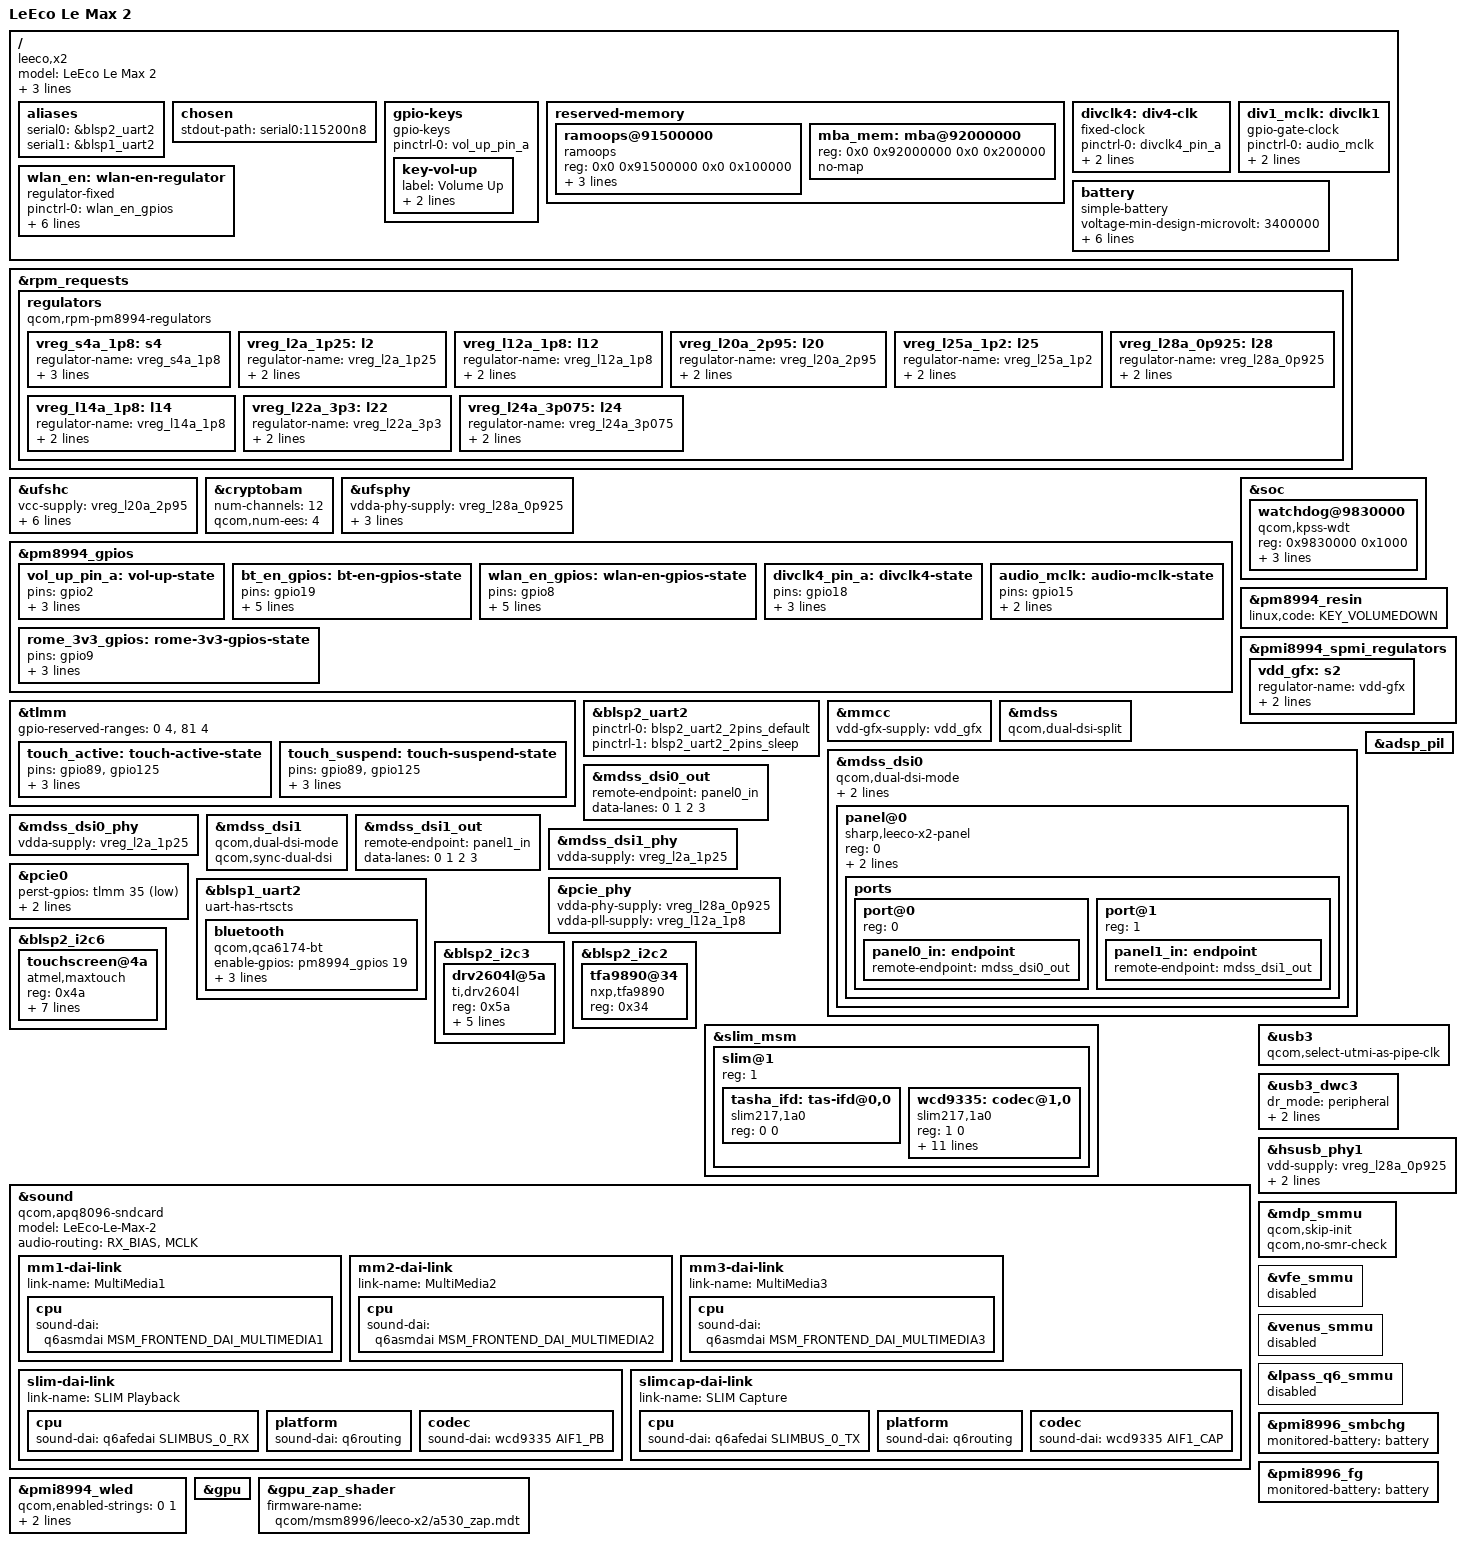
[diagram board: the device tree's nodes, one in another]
// SPDX-License-Identifier: (GPL-2.0+ OR BSD-3-Clause)
/*
 * LeEco Le Max 2 (x2 / LEX820)
 *
 * MSM8996 v3 + PMI8996, 5.7" 1440x2560 dual-DSI panel.
 *
 * Board identification values were read from the live device:
 *   /proc/device-tree/qcom,msm-id    = <0xf6 0x30001>
 *   /proc/device-tree/qcom,board-id  = <0x08 0x2e>
 *   /proc/device-tree/qcom,pmic-id   = <0x20009 0x10013 0x00 0x00>
 *
 * NOTE 1: msm8996-v3.0.dtsi pins qcom,msm-id to <246 0x30000>, but this
 * device reports <246 0x30001>. We therefore include plain msm8996.dtsi
 * (the 3.1 revision) and set the correct msm-id ourselves. This matches
 * what oneplus3 does (it also uses 0x30001 via msm8996.dtsi).
 *
 * NOTE 2: Three DTB variants share board-id 0x2e in the stock boot.img
 * (v3+PMI8996, v3+PMI8994, 8996Pro+PMI8996). The device actually boots the
 * v3+PMI8996 one, which is what we model here.
 */

/dts-v1/;

#include "msm8996.dtsi"
#include "pm8994.dtsi"
#include "pmi8994.dtsi"
#include "pmi8996.dtsi"
#include <dt-bindings/gpio/gpio.h>
#include <dt-bindings/input/input.h>
#include <dt-bindings/input/ti-drv260x.h>
#include <dt-bindings/interrupt-controller/irq.h>
#include <dt-bindings/pinctrl/qcom,pmic-gpio.h>
#include <dt-bindings/sound/qcom,q6afe.h>
#include <dt-bindings/sound/qcom,q6asm.h>
#include <dt-bindings/sound/qcom,wcd9335.h>

/ {
	model = "LeEco Le Max 2";
	compatible = "leeco,x2", "qcom,msm8996";
	chassis-type = "handset";

	qcom,msm-id = <246 0x30001>;
	qcom,board-id = <0x08 0x2e>;

	aliases {
		/* BLSP2 UART2 is the debug console and keeps ttyMSM0. */
		serial0 = &blsp2_uart2;
		/* BLSP1 UART2 is the QCA6174 HCI transport and must not share
		 * line 0 with the console. */
		serial1 = &blsp1_uart2;
	};

	chosen {
		stdout-path = "serial0:115200n8";
	};

	gpio-keys {
		compatible = "gpio-keys";
		pinctrl-names = "default";
		pinctrl-0 = <&vol_up_pin_a>;

		key-vol-up {
			label = "Volume Up";
			linux,code = <KEY_VOLUMEUP>;
			/* vendor mtp-le-common.dtsi:710 - vol_up is pm8994 gpio2 */
			gpios = <&pm8994_gpios 2 GPIO_ACTIVE_LOW>;
		};
	};

	reserved-memory {
		#address-cells = <2>;
		#size-cells = <2>;
		ranges;

		/*
		 * ramoops: MUST live at 0x91500000 - that is where the stock
		 * 3.18 kernel and TWRP look for console-ramoops on this device
		 * (msm8996-le-common.dtsi: ramoops_region@91500000). Anything
		 * written elsewhere is invisible after rebooting back to
		 * Android/TWRP.
		 *
		 * The sub-buffer sizes MUST match the stock 3.18 kernel's
		 * ramoops module params exactly (console_size=0x40000,
		 * record_size=0x10000, pmsg_size=0x20000, ecc=0) and the
		 * kernel's allocation order (dmesg records first, then
		 * console, then pmsg) so that records written by one kernel
		 * are parseable by the other. In particular console-size
		 * 0x60000 made our records unreadable by 3.18.
		 */
		ramoops@91500000 {
			compatible = "ramoops";
			reg = <0x0 0x91500000 0x0 0x100000>;
			console-size = <0x40000>;
			record-size  = <0x10000>;
			pmsg-size    = <0x20000>;
		};

		/* relocated from 0x91500000, which the stock ramoops uses;
		 * same label kept so the mba remoteproc reference resolves */
		/delete-node/ mba@91500000;
		mba_mem: mba@92000000 {
			reg = <0x0 0x92000000 0x0 0x200000>;
			no-map;
		};
	};
};

/*
 * PM8994 RPM regulators.
 *
 * These labels are NOT inherited from pm8994.dtsi - every msm8996 board
 * declares the rails it actually uses under &rpm_requests. We only define
 * the ones referenced below; the voltage values match the oneplus3 and
 * xiaomi-msm8996 boards, which use an identical UFS supply arrangement.
 */
&rpm_requests {
	regulators {
		compatible = "qcom,rpm-pm8994-regulators";

		vreg_s4a_1p8: s4 {
			regulator-name = "vreg_s4a_1p8";
			regulator-min-microvolt = <1800000>;
			regulator-max-microvolt = <1800000>;
			regulator-always-on;
		};

		vreg_l2a_1p25: l2 {
			regulator-name = "vreg_l2a_1p25";
			regulator-min-microvolt = <1250000>;
			regulator-max-microvolt = <1250000>;
		};

		vreg_l12a_1p8: l12 {
			regulator-name = "vreg_l12a_1p8";
			regulator-min-microvolt = <1800000>;
			regulator-max-microvolt = <1800000>;
		};

		vreg_l20a_2p95: l20 {
			regulator-name = "vreg_l20a_2p95";
			regulator-min-microvolt = <2950000>;
			regulator-max-microvolt = <2950000>;
		};

		vreg_l25a_1p2: l25 {
			regulator-name = "vreg_l25a_1p2";
			regulator-min-microvolt = <1200000>;
			regulator-max-microvolt = <1200000>;
		};

		vreg_l28a_0p925: l28 {
			regulator-name = "vreg_l28a_0p925";
			regulator-min-microvolt = <925000>;
			regulator-max-microvolt = <925000>;
		};

		/* rails for peripherals: touch (l14/l22), usb dpdm (l24) */
		vreg_l14a_1p8: l14 {
			regulator-name = "vreg_l14a_1p8";
			regulator-min-microvolt = <1800000>;
			regulator-max-microvolt = <1800000>;
		};

		vreg_l22a_3p3: l22 {
			regulator-name = "vreg_l22a_3p3";
			regulator-min-microvolt = <3300000>;
			regulator-max-microvolt = <3300000>;
		};

		vreg_l24a_3p075: l24 {
			regulator-name = "vreg_l24a_3p075";
			regulator-min-microvolt = <3075000>;
			regulator-max-microvolt = <3075000>;
		};
	};
};

/*
 * UFS: Samsung KLUCG4J1CB-B0B1, 6 LUNs.
 * This is the first thing that must work - without rootfs there is no boot.
 * Supply assignment matches oneplus3 / xiaomi-msm8996, which use the same
 * PM8994 rail layout for UFS.
 */
&ufshc {
	status = "okay";

	vcc-supply = <&vreg_l20a_2p95>;
	vccq-supply = <&vreg_l25a_1p2>;
	vccq2-supply = <&vreg_s4a_1p8>;
	vdd-hba-supply = <&vreg_l25a_1p2>;

	vcc-max-microamp = <600000>;
	vccq-max-microamp = <450000>;
	vccq2-max-microamp = <450000>;
};

/*
 * CE1 BAM. The crypto engine uses pipes 6/7, and the BAM block itself is
 * controlled by the secure firmware, so the Linux side only needs the channel
 * map. msm8937/msm8998 use the same CE BAM topology (12 channels, 4 EEs).
 */
&cryptobam {
	num-channels = <12>;
	qcom,num-ees = <4>;
};

&ufsphy {
	status = "okay";

	vdda-phy-supply = <&vreg_l28a_0p925>;
	vdda-pll-supply = <&vreg_l12a_1p8>;

	vdda-phy-max-microamp = <89700>;
	vdda-pll-max-microamp = <18300>;
};

/* Volume keys live on PMIC GPIOs */
&pm8994_gpios {
	vol_up_pin_a: vol-up-state {
		pins = "gpio2";
		function = PMIC_GPIO_FUNC_NORMAL;
		bias-pull-up;
		input-enable;
	};
};

&tlmm {
	gpio-reserved-ranges = <0 4>, <81 4>;
};

/*
 * APSS hardware watchdog. The vendor 3.18 DTS exposes this at 0x9830000
 * as "qcom,wdt"; mainline has no node, so PSCI reset is the only restart
 * path and a failed PSCI reset leaves the SoC spinning in machine_restart().
 */
&soc {
	watchdog@9830000 {
		compatible = "qcom,kpss-wdt";
		reg = <0x9830000 0x1000>;
		interrupts = <0 28 1>, <0 29 1>;
		clocks = <&sleep_clk>;
		timeout-sec = <30>;
	};
};

/*
 * Debug UART - invaluable when the display does not work yet.
 *
 * The x2 console is BLSP2_UART1 (uart8) on gpio4/5 = mainline blsp2_uart2
 * (serial@75b0000), exactly as the vendor pinctrl uart_console_active and
 * the downstream uart_dm_init(8, BLSP2_UART1_BASE) both show. blsp1_uart2 is the
 * BT/hs-uart on gpio41-44 - enabling it was wrong.
 */
&blsp2_uart2 {
	pinctrl-names = "default", "sleep";
	pinctrl-0 = <&blsp2_uart2_2pins_default>;
	pinctrl-1 = <&blsp2_uart2_2pins_sleep>;
	status = "okay";
};

&pm8994_resin {
	status = "okay";
	linux,code = <KEY_VOLUMEDOWN>;
};

/*
 * GPU supply: PMI8994 S2 is VDD_GFX. The MMCC GPU_GX_GDSC (and therefore
 * the Adreno GX rail) is parented to this regulator on every other
 * msm8996 board. Without it the GDSC comes up on a dummy supply and the
 * first RBCCU/GPMU power-up can reset the whole PMIC.
 */
&pmi8994_spmi_regulators {
	vdd_gfx: s2 {
		regulator-name = "vdd-gfx";
		regulator-min-microvolt = <980000>;
		regulator-max-microvolt = <1230000>;
	};
};

&mmcc {
	vdd-gfx-supply = <&vdd_gfx>;
};

/*
 * Display: Sharp 1440x2560 dual-DSI.
 *
 * Values below come from the vendor kernel device tree
 * (msm8996-le_x2-pvt.dtsi), which is what a retail PVT unit runs:
 *   qcom,platform-reset-gpio = <&tlmm 24 0>
 *   qcom,platform-te-gpio    = <&tlmm 97 0>
 *
 * The panel has no separate enable GPIO on x2 (the vendor dtsi deletes
 * qcom,platform-bklight-en-gpio), so only reset is wired up here.
 */
&mdss {
	status = "okay";

	/*
	 * MDP5 drives INTF0 and INTF1 from a single CRTC for this panel,
	 * one CTL per interface (see kernel/patches/0005-mdp5-dual-intf.patch
	 * and docs/mdp5-dual-intf-plan.md).
	 */
	qcom,dual-dsi-split;
};

&mdss_dsi0 {
	status = "okay";

	/*
	 * Bonded dual-DSI: dsi_mgr_parse_of() reads these from the DSI
	 * *controller* node, not from the panel node. Bonding gives us a
	 * single encoder/connector and makes dsi_host halve the timings and
	 * the pixel clock for each link; MDP5 then feeds INTF0 and INTF1.
	 */
	qcom,dual-dsi-mode;
	qcom,master-dsi;
	qcom,sync-dual-dsi;

	/*
	 * NOTE: do NOT give the DSI hosts explicit vddio/vdda/vcca supplies.
	 * With them bound, msm_dsi toggles L14/L2/L28 around host power-on and
	 * the link comes up silently dead (backlight on, no picture, fbcon then
	 * reports fb_set_par -EBUSY). The vendor dtsi deletes vddio-supply for
	 * this board (rails are always-on); dummy regulators work.
	 *
	 * NOTE 2: an earlier attempt enabled bonding without splitting the
	 * MDP5 side: INTF0 alone carried the full 1440-wide frame while
	 * dsi_host expected 984 lines per link, so DSI flooded
	 * dsi_err_worker status=4 (FIFO) with no picture. The mode now uses
	 * doubled horizontal porches (htotal 1968) and patch 0005 programs
	 * both INTFs with the per-link timing; keep them together.
	 */
	panel@0 {
		compatible = "sharp,leeco-x2-panel";
		reg = <0>;

		reset-gpios = <&tlmm 24 GPIO_ACTIVE_LOW>;

		/*
		 * WLED is the only backlight source on x2; the driver calls
		 * drm_panel_of_backlight() and follows this phandle.
		 */
		backlight = <&pmi8994_wled>;

		ports {
			#address-cells = <1>;
			#size-cells = <0>;

			port@0 {
				reg = <0>;
				panel0_in: endpoint {
					remote-endpoint = <&mdss_dsi0_out>;
				};
			};

			port@1 {
				reg = <1>;
				panel1_in: endpoint {
					remote-endpoint = <&mdss_dsi1_out>;
				};
			};
		};
	};
};

&mdss_dsi0_out {
	remote-endpoint = <&panel0_in>;
	data-lanes = <0 1 2 3>;
};

&mdss_dsi0_phy {
	status = "okay";

	vdda-supply = <&vreg_l2a_1p25>;
};

&mdss_dsi1 {
	status = "okay";

	/* slave link of the bonded pair */
	qcom,dual-dsi-mode;
	qcom,sync-dual-dsi;
};

&mdss_dsi1_out {
	remote-endpoint = <&panel1_in>;
	data-lanes = <0 1 2 3>;
};

&mdss_dsi1_phy {
	status = "okay";

	vdda-supply = <&vreg_l2a_1p25>;
};

/*
 * ======== Peripherals (vendor evidence in docs/peripherals-dts-notes.md) ========
 */

/ {
	/* BT sleep clock: PM8994 GPIO18 func2 = 32.768kHz output
	 * (vendor mtp-le-common.dtsi gpio@d100 "Rome Sleep Clock"). */
	divclk4: div4-clk {
		compatible = "fixed-clock";
		pinctrl-names = "default";
		pinctrl-0 = <&divclk4_pin_a>;
		#clock-cells = <0>;
		clock-frequency = <32768>;
		clock-output-names = "divclk4";
	};

	/* WCD9335 master clock: PM8994 GPIO15 func1 gates RPM_SMD_DIV_CLK1
	 * (vendor gpio@ce00, mclk 9.6MHz). */
	div1_mclk: divclk1 {
		compatible = "gpio-gate-clock";
		pinctrl-names = "default";
		pinctrl-0 = <&audio_mclk>;
		clocks = <&rpmcc RPM_SMD_DIV_CLK1>;
		#clock-cells = <0>;
		enable-gpios = <&pm8994_gpios 15 GPIO_ACTIVE_HIGH>;
	};

	/* QCA6174 WLAN_EN: PM8994 GPIO8 (vendor gpio@c700, vin = S4 1.8V). */
	wlan_en: wlan-en-regulator {
		compatible = "regulator-fixed";
		pinctrl-names = "default";
		pinctrl-0 = <&wlan_en_gpios>;
		regulator-name = "wlan-en-regulator";
		regulator-min-microvolt = <1800000>;
		regulator-max-microvolt = <1800000>;

		gpio = <&pm8994_gpios 8 GPIO_ACTIVE_HIGH>;

		startup-delay-us = <70000>;
		enable-active-high;
	};
};

/* WiFi: QCA6174 on PCIe0 (ath10k_pci). PERST=GPIO35, CLKREQ=36, WAKE=37
 * are wired by the dtsi pcie0 pin groups. */
&pcie0 {
	status = "okay";

	perst-gpios = <&tlmm 35 GPIO_ACTIVE_LOW>;
	vddpe-3v3-supply = <&wlan_en>;
	vdda-supply = <&vreg_l28a_0p925>;
};

&pcie_phy {
	status = "okay";

	vdda-phy-supply = <&vreg_l28a_0p925>;
	vdda-pll-supply = <&vreg_l12a_1p8>;
};

/*
 * Bluetooth: QCA Rome (qca6174) on BLSP1 UART2 (serial@7570000, gpio41-44).
 * BT_EN = PM8994 GPIO19. The console is blsp2_uart2 (gpio4/5) - no clash.
 */
&blsp1_uart2 {
	uart-has-rtscts;
	status = "okay";

	bluetooth {
		compatible = "qcom,qca6174-bt";

		enable-gpios = <&pm8994_gpios 19 GPIO_ACTIVE_HIGH>;

		clocks = <&divclk4>;
		max-speed = <1000000>;

		/* QCA6174 returns an all-zero BD_ADDR unless its NVM image
		 * supplied one; Linux then marks the controller unconfigured.
		 * Use a locally administered address so hci0 can be brought up.
		 * Symmetric bytes avoid the local-bd-address endian ambiguity. */
		local-bd-address = [ 02 00 00 00 00 02 ];
	};
};

/*
 * Touchscreen: Atmel mXT (T100) @0x4a on BLSP2 QUP6 (gpio87/88).
 * Vendor: IRQ = GPIO125 level-low, RESET = GPIO89, AVDD = l22 (3.3V),
 * VDD_IO = l14 (1.8V).
 */
&blsp2_i2c6 {
	status = "okay";

	touchscreen@4a {
		compatible = "atmel,maxtouch";
		reg = <0x4a>;

		interrupt-parent = <&tlmm>;
		interrupts = <125 IRQ_TYPE_LEVEL_LOW>;
		reset-gpios = <&tlmm 89 GPIO_ACTIVE_LOW>;

		vdda-supply = <&vreg_l22a_3p3>;
		vdd-supply = <&vreg_l14a_1p8>;

		pinctrl-names = "default", "sleep";
		pinctrl-0 = <&touch_active>;
		pinctrl-1 = <&touch_suspend>;
	};
};

/* Vibration: TI DRV2604L @0x5a on BLSP2 QUP3 (gpio51/52), enable GPIO38,
 * LRA actuator, rated 1600mV / overdrive 2600mV (vendor dvt1 dtsi). */
&blsp2_i2c3 {
	status = "okay";

	drv2604l@5a {
		compatible = "ti,drv2604l";
		reg = <0x5a>;

		enable-gpios = <&tlmm 38 GPIO_ACTIVE_HIGH>;
		mode = <DRV260X_LRA_NO_CAL_MODE>;
		library-sel = <DRV260X_LIB_EMPTY>;
		vib-rated-mv = <1600>;
		vib-overdrive-mv = <2600>;
	};
};

/* Speaker amp: NXP TFA9890 @0x34 on BLSP2 QUP2 (gpio6/7). The mainline
 * tfa989x driver needs neither the vendor IRQ(122)/reset(90) gpios nor a
 * supply. No mainline 8996 sound card links it yet - speaker stays dead
 * until card work is done; headphones route via the WCD. */
&blsp2_i2c2 {
	status = "okay";

	tfa9890@34 {
		compatible = "nxp,tfa9890";
		reg = <0x34>;
		#sound-dai-cells = <0>;
	};
};

/*
 * Audio: WCD9335 (tasha) on SLIMbus NGD. Codec elemental addr 00 01 A0 01
 * 17 02 == slim217,1a0 reg <1 0>; all static supplies = s4 1.8V; reset =
 * GPIO64, intr1 = GPIO54. Requires adsp firmware for the Q6 dais.
 */
&adsp_pil {
	status = "okay";
};

&slim_msm {
	status = "okay";

	slim@1 {
		reg = <1>;
		#address-cells = <2>;
		#size-cells = <0>;

		tasha_ifd: tas-ifd@0,0 {
			compatible = "slim217,1a0";
			reg = <0 0>;
		};

		wcd9335: codec@1,0 {
			compatible = "slim217,1a0";
			reg = <1 0>;

			clock-names = "mclk", "slimbus";
			clocks = <&div1_mclk>,
				 <&rpmcc RPM_SMD_BB_CLK1>;
			interrupt-parent = <&tlmm>;
			interrupts = <54 IRQ_TYPE_LEVEL_HIGH>;
			interrupt-names = "intr1";

			pinctrl-0 = <&cdc_reset_active &wcd_intr_default>;
			pinctrl-names = "default";

			reset-gpios = <&tlmm 64 GPIO_ACTIVE_LOW>;
			slim-ifc-dev = <&tasha_ifd>;

			#sound-dai-cells = <1>;

			vdd-buck-supply = <&vreg_s4a_1p8>;
			vdd-buck-sido-supply = <&vreg_s4a_1p8>;
			vdd-tx-supply = <&vreg_s4a_1p8>;
			vdd-rx-supply = <&vreg_s4a_1p8>;
			vdd-io-supply = <&vreg_s4a_1p8>;
		};
	};
};

&sound {
	compatible = "qcom,apq8096-sndcard";
	model = "LeEco-Le-Max-2";
	audio-routing = "RX_BIAS", "MCLK";

	mm1-dai-link {
		link-name = "MultiMedia1";
		cpu {
			sound-dai = <&q6asmdai MSM_FRONTEND_DAI_MULTIMEDIA1>;
		};
	};

	mm2-dai-link {
		link-name = "MultiMedia2";
		cpu {
			sound-dai = <&q6asmdai MSM_FRONTEND_DAI_MULTIMEDIA2>;
		};
	};

	mm3-dai-link {
		link-name = "MultiMedia3";
		cpu {
			sound-dai = <&q6asmdai MSM_FRONTEND_DAI_MULTIMEDIA3>;
		};
	};

	slim-dai-link {
		link-name = "SLIM Playback";
		cpu {
			sound-dai = <&q6afedai SLIMBUS_0_RX>;
		};

		platform {
			sound-dai = <&q6routing>;
		};

		codec {
			sound-dai = <&wcd9335 AIF1_PB>;
		};
	};

	slimcap-dai-link {
		link-name = "SLIM Capture";
		cpu {
			sound-dai = <&q6afedai SLIMBUS_0_TX>;
		};

		platform {
			sound-dai = <&q6routing>;
		};

		codec {
			sound-dai = <&wcd9335 AIF1_CAP>;
		};
	};
};

/* USB: Type-C, high-speed only (vendor never wires the QMP SS path;
 * oneplus3 is HS-only upstream too). VBUS is switched by the Cypress CCG2
 * CC chip in hardware, so no vbus-supply/extcon. Peripheral mode keeps
 * ADB available without role switching. */
&usb3 {
	qcom,select-utmi-as-pipe-clk;
	status = "okay";
};

&usb3_dwc3 {
	dr_mode = "peripheral";
	maximum-speed = "high-speed";
	phys = <&hsusb_phy1>;
	phy-names = "usb2-phy";
};

&hsusb_phy1 {
	status = "okay";

	vdd-supply = <&vreg_l28a_0p925>;
	vdda-pll-supply = <&vreg_l12a_1p8>;
	vdda-phy-dpdm-supply = <&vreg_l24a_3p075>;
};

&tlmm {
	touch_active: touch-active-state {
		pins = "gpio89", "gpio125";
		function = "gpio";
		drive-strength = <16>;
		bias-pull-up;
	};

	touch_suspend: touch-suspend-state {
		pins = "gpio89", "gpio125";
		function = "gpio";
		drive-strength = <2>;
		bias-disable;
	};
};

&pm8994_gpios {
	bt_en_gpios: bt-en-gpios-state {
		pins = "gpio19";
		function = PMIC_GPIO_FUNC_NORMAL;
		output-low;
		power-source = <PM8994_GPIO_S4>;
		qcom,drive-strength = <PMIC_GPIO_STRENGTH_LOW>;
		bias-pull-down;
	};

	wlan_en_gpios: wlan-en-gpios-state {
		pins = "gpio8";
		function = PMIC_GPIO_FUNC_NORMAL;
		output-low;
		power-source = <PM8994_GPIO_S4>;
		qcom,drive-strength = <PMIC_GPIO_STRENGTH_LOW>;
		bias-pull-down;
	};

	/* Rome sleep clock output, GPIO18 func2 */
	divclk4_pin_a: divclk4-state {
		pins = "gpio18";
		function = PMIC_GPIO_FUNC_FUNC2;
		bias-disable;
		power-source = <PM8994_GPIO_S4>;
	};

	/* audio MCLK output, GPIO15 func1 */
	audio_mclk: audio-mclk-state {
		pins = "gpio15";
		function = PMIC_GPIO_FUNC_FUNC1;
		power-source = <PM8994_GPIO_S4>;
	};

	/*
	 * Rome 3.3V control, GPIO9 (vendor sets it high; ath10k has no DT
	 * regulator hook for this rail, so force it via pinctrl - the
	 * bootloader already leaves it high).
	 */
	rome_3v3_gpios: rome-3v3-gpios-state {
		pins = "gpio9";
		function = PMIC_GPIO_FUNC_NORMAL;
		output-high;
		power-source = <PM8994_GPIO_VPH>;
	};
};

/*
 * The display SMMU is mandatory: MDP5 refuses to initialise without it.
 * A boot with mdp_smmu disabled prints
 *   [drm:mdp5_kms_init] MDP5 version v1.7
 *   [drm] no IOMMU, bailing out
 * and then tears the DRM device down again, so the panel never binds and the
 * screen stays black. Earlier bring-up notes claimed arm-smmu hangs while
 * resetting d00000 before UFS/USB probe; if that happens again the console log
 * survives in ramoops (0x91500000) and can be read back after a cold reset.
 *
 * vfe/venus/ADSP SMMUs stay off: nothing needs them yet and each one is
 * another chance to hang early in boot.
 */
&mdp_smmu	{
	status = "okay";

	/*
	 * The SMMU is already set up by the bootloader; skipping the context
	 * bank reset avoids the register writes that hang d00000 on this board.
	 * Same story for the SMR mask probe: it writes SMR/S2CR and wedges the
	 * block right after reset, so take the fixed mask values instead.
	 */
	qcom,skip-init;
	qcom,no-smr-check;
};
&vfe_smmu	{ status = "disabled"; };
&venus_smmu	{ status = "disabled"; };
&lpass_q6_smmu	{ status = "disabled"; };

/*
 * PMIC: charger, fuel gauge and WLED backlight.
 *
 * All three blocks exist in the shared PMI8994 dtsi but ship disabled, which
 * is why a Debian boot has no battery percentage and Linux could not touch
 * the backlight. pmi8996.dtsi re-labels the two charger/fuel-gauge nodes with
 * the PMI8996 compatibles, so reference those labels here.
 *
 *   qcom-smbchg     CONFIG_CHARGER_QCOM_SMBCHG (already =y)
 *   qcom_fg         CONFIG_BATTERY_QCOM_FG     (was =m, made =y)
 *   qcom-wled       CONFIG_BACKLIGHT_QCOM_WLED (already =y)
 *
 * Both drivers call power_supply_get_battery_info() and follow a
 * `monitored-battery` phandle, so the pack description below is required:
 * without it smbchg fails with "Failed to get battery info: -ENOENT" and
 * never registers, which leaves the board with no battery or charger at all.
 */
&pmi8996_smbchg {
	status = "okay";

	monitored-battery = <&battery>;
};

&pmi8996_fg {
	status = "okay";

	monitored-battery = <&battery>;
};

&pmi8994_wled {
	status = "okay";

	/*
	 * Match the panel's real hardware: four LED strings driven at 25 mA
	 * each out of a 29.5 V boost. The driver defaults (10 mA, 29.6 V)
	 * leave the panel visibly dark, and downstream mokee uses the same
	 * 25 mA / 29.5 V combination on x2. The boost switching frequency
	 * keeps its default (index 11 == 800 kHz, as downstream).
	 */
	qcom,enabled-strings = <0 1>;
	qcom,current-limit-microamp = <25000>;
	qcom,ovp-millivolt = <29500>;

	/*
	 * x2 uses the PMIC's internal PFET: the bootloader leaves TEST1 at 0
	 * and the panel lights up, while selecting the external-PFET DTEST2
	 * mode (qcom,external-pfet from msm8996.dtsi) leaves every string dark.
	 */
	/delete-property/ qcom,external-pfet;
};

/*
 * Le Max 2 pack: 3.85 V nominal, 4.35 V charge limit, 3100 mAh.
 * Values from the vendor charger/BMS configuration.
 */
/ {
	battery: battery {
		compatible = "simple-battery";

		voltage-min-design-microvolt = <3400000>;
		voltage-max-design-microvolt = <4350000>;
		energy-full-design-microwatt-hours = <11780000>;
		charge-full-design-microamp-hours = <3100000>;

		precharge-current-microamp = <200000>;
		constant-charge-current-max-microamp = <2000000>;
		charge-term-current-microamp = <200000>;
	};
};


&gpu {
	status = "okay";
};

&gpu_zap_shader {
	firmware-name = "qcom/msm8996/leeco-x2/a530_zap.mdt";
};
